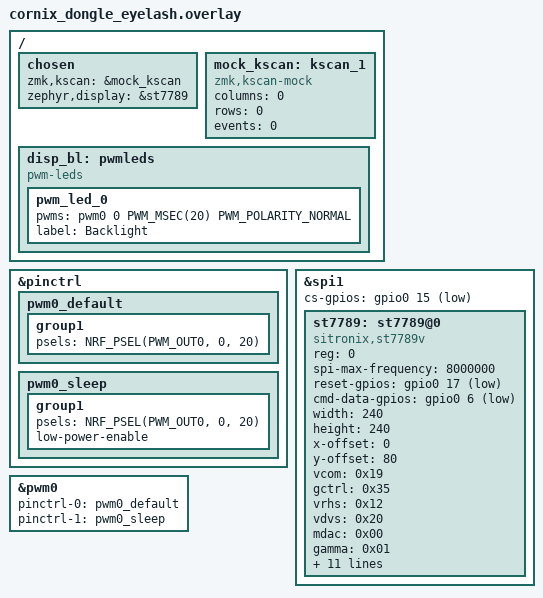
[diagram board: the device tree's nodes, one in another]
#include <dt-bindings/zmk/matrix_transform.h>
#include <dt-bindings/gpio/gpio.h>

/{
    chosen {
        zmk,kscan = &mock_kscan;
        zephyr,display = &st7789;
    };
    mock_kscan: kscan_1 {
        compatible = "zmk,kscan-mock";
        columns = <0>;
        rows = <0>;
        events = <0>;
    };

    disp_bl: pwmleds {
        compatible = "pwm-leds";
        pwm_led_0 {
            pwms = <&pwm0 0 PWM_MSEC(20) PWM_POLARITY_NORMAL>;
            label = "Backlight";
        };
    };
};

&pinctrl {
    pwm0_default: pwm0_default {
        group1 {
            psels = <NRF_PSEL(PWM_OUT0, 0, 20)>;
        };
    };

    pwm0_sleep: pwm0_sleep {
        group1 {
            psels = <NRF_PSEL(PWM_OUT0, 0, 20)>;
            low-power-enable;
        };
    };
};

&spi1 {
    status = "okay";
    cs-gpios = <&gpio0 15 GPIO_ACTIVE_LOW>;

    st7789: st7789@0 {
        compatible = "sitronix,st7789v";
        reg = <0>;
        spi-max-frequency = <8000000>;
        reset-gpios = <&gpio0 17 GPIO_ACTIVE_LOW>;
        cmd-data-gpios = <&gpio0 6 GPIO_ACTIVE_LOW>;
        width = <240>;
        height = <240>;
        x-offset = <0>;
        y-offset = <80>;
        vcom = <0x19>;
        gctrl = <0x35>;
        vrhs = <0x12>;
        vdvs = <0x20>;
        mdac = <0x00>;
        gamma = <0x01>;
        colmod = <0x55>;
        lcm = <0x2c>;
        porch-param = [0c 0c 00 33 33];
        cmd2en-param = [5a 69 02 01];
        pwctrl1-param = [a4 a1];
        pvgam-param = [D0 04 0D 11 13 2B 3F 54 4C 18 0D 0B 1F 23];
        nvgam-param = [D0 04 0C 11 13 2C 3F 44 51 2F 1F 1F 20 23];
        ram-param = [00 F0];
        rgb-param = [CD 08 14];
    };
};

&pwm0 {
    status = "okay";
    pinctrl-0 = <&pwm0_default>;
    pinctrl-1 = <&pwm0_sleep>;
    pinctrl-names = "default", "sleep";
};

//vim: set ft=dts:
